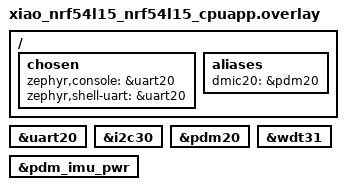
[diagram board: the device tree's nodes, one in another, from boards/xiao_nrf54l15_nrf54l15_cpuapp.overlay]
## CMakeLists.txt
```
# SPDX-License-Identifier: Apache-2.0

cmake_minimum_required(VERSION 3.20.0)

set(PM_STATIC_YML_FILE ${CMAKE_CURRENT_SOURCE_DIR}/pm_static.yml)

find_package(Zephyr REQUIRED HINTS $ENV{ZEPHYR_BASE})
project(nrf54_handy)

target_sources(app PRIVATE
    src/main.c
    src/audio_capture.c
    src/adpcm.c
)
```

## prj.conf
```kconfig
# Zephyr Kernel Configuration for XIAO nRF54L15 Sense - nrf54-handy (Handy BLE)

CONFIG_MAIN_STACK_SIZE=4096

# Heap (BLE stack + MCUmgr + audio needs memory)
CONFIG_HEAP_MEM_POOL_SIZE=65536
CONFIG_SYSTEM_WORKQUEUE_STACK_SIZE=4096

# Logging and console (UART20 on XIAO nRF54L15)
CONFIG_LOG=y
CONFIG_LOG_MODE_DEFERRED=n
CONFIG_CONSOLE=y
CONFIG_UART_CONSOLE=y
CONFIG_PRINTK=y
CONFIG_CBPRINTF_FP_SUPPORT=y

# Peripherals
CONFIG_GPIO=y
CONFIG_PINCTRL=y

# Audio (PDM microphone)
CONFIG_AUDIO=y
CONFIG_AUDIO_DMIC=y

# Bluetooth Low Energy
CONFIG_BT=y
CONFIG_BT_PERIPHERAL=y
CONFIG_BT_BROADCASTER=y
CONFIG_BT_MAX_CONN=1
CONFIG_BT_SMP=n
CONFIG_BT_GATT_DYNAMIC_DB=y
CONFIG_BT_DEVICE_NAME="XIAOVoice"
CONFIG_BT_DEVICE_NAME_DYNAMIC=y
CONFIG_BT_DEVICE_NAME_MAX=20
CONFIG_BT_GATT_CLIENT=y

# BLE MTU (OTA transfer efficiency + audio throughput)
CONFIG_BT_L2CAP_TX_MTU=244
CONFIG_BT_BUF_ACL_RX_SIZE=251
CONFIG_BT_BUF_ACL_TX_SIZE=251
CONFIG_BT_CTLR_DATA_LENGTH_MAX=251
CONFIG_BT_L2CAP_TX_BUF_COUNT=4
CONFIG_BT_ATT_TX_COUNT=4
CONFIG_BT_CONN_TX_MAX=4

# MCUmgr (SMP server for BLE OTA)
CONFIG_MCUMGR=y
CONFIG_MCUMGR_TRANSPORT_BT=y
CONFIG_MCUMGR_GRP_IMG=y
CONFIG_MCUMGR_GRP_IMG_VERBOSE_ERR=y
CONFIG_MCUBOOT_IMGTOOL_SIGN_VERSION="0.0.1+0"
CONFIG_MCUMGR_GRP_OS=y

# MCUmgr dependencies
CONFIG_IMG_MANAGER=y
CONFIG_MCUBOOT_IMG_MANAGER=y
CONFIG_FLASH=y
CONFIG_FLASH_MAP=y
CONFIG_STREAM_FLASH=y
CONFIG_NRFX_RRAMC=n
CONFIG_NRF_RRAM_READYNEXT_TIMEOUT_VALUE=0
CONFIG_NET_BUF=y
CONFIG_ZCBOR=y

# Settings persistence (image confirm state survives reboot)
CONFIG_SETTINGS=y
CONFIG_SETTINGS_FCB=y
CONFIG_FCB=y

# Watchdog timer
CONFIG_WATCHDOG=y

# Hardware info (read reset cause)
CONFIG_HWINFO=y

# I2C + IMU (LSM6DS3TR-C)
CONFIG_I2C=y
CONFIG_SENSOR=y
CONFIG_LSM6DSL=y
CONFIG_LSM6DSL_TRIGGER_GLOBAL_THREAD=y

# Regulator API (pdm_imu_pwr BLE-connected power management)
CONFIG_REGULATOR=y
```

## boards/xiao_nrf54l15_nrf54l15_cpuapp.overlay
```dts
/*
 * Device Tree Overlay for Seeed Studio XIAO nRF54L15 Sense
 * nrf54-handy: PDM microphone + IMU
 *
 * Board DTS already enables uart20, i2c30, lsm6ds3tr_c, pdm20, and imu0 alias.
 * This overlay adds the dmic20 alias used by audio_capture.c.
 */

#include <dt-bindings/gpio/gpio.h>

/ {
	chosen {
		zephyr,console = &uart20;
		zephyr,shell-uart = &uart20;
	};

	aliases {
		dmic20 = &pdm20;
	};
};

&uart20 {
	status = "okay";
};

&i2c30 {
	status = "okay";
};

&pdm20 {
	status = "okay";
};

&wdt31 {
	status = "okay";
};

/* Remove regulator-boot-on so pdm_imu_pwr starts OFF.
 * Firmware enables it explicitly on BLE connect via regulator_enable(). */
&pdm_imu_pwr {
	/delete-property/ regulator-boot-on;
};
```

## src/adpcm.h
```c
/*
 * ADPCM Codec for Voice Bridge BLE
 * IMA ADPCM 4-bit encoding/decoding
 */

#ifndef ADPCM_H
#define ADPCM_H

#include <stdint.h>
#include <stddef.h>

#ifdef __cplusplus
extern "C" {
#endif

/* ADPCM state structure */
typedef struct {
    int32_t predictor;
    int32_t step_size;
} adpcm_state_t;

/* Initialize ADPCM state */
void adpcm_init_state(adpcm_state_t *state);

/* Encode 16-bit PCM to 4-bit ADPCM */
size_t adpcm_encode(adpcm_state_t *state, const int16_t *input,
                    size_t num_samples, uint8_t *output);

/* Decode 4-bit ADPCM to 16-bit PCM */
size_t adpcm_decode(adpcm_state_t *state, const uint8_t *input,
                    size_t num_bytes, int16_t *output);

#ifdef __cplusplus
}
#endif

#endif /* ADPCM_H */
```

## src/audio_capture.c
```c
/*
 * Audio Capture for Voice Bridge BLE
 * PDM Microphone via Zephyr DMIC API on nRF54L15
 *
 * Ported from nordic-main/src/audio_capture.c:
 *   - DT alias: dmic0 → dmic20
 *   - Fallback node: pdm0 → pdm20
 *   - PDM channel: PDM_CHAN_RIGHT → PDM_CHAN_LEFT
 */

#include <zephyr/kernel.h>
#include <zephyr/device.h>
#include <zephyr/audio/dmic.h>
#include <zephyr/logging/log.h>

#include "audio_capture.h"

LOG_MODULE_REGISTER(audio_capture, LOG_LEVEL_INF);

/* ============================================================================
 * Configuration
 * ============================================================================ */

#define SAMPLE_RATE         16000
#define SAMPLE_BITS         16
#define CHANNELS            1
#define BYTES_PER_SAMPLE    sizeof(int16_t)

/* 20ms frame = 320 samples = 640 bytes */
#define FRAME_MS            20
#define FRAME_SAMPLES       (SAMPLE_RATE * FRAME_MS / 1000)
#define FRAME_BYTES         (FRAME_SAMPLES * BYTES_PER_SAMPLE * CHANNELS)

/* Memory slab for DMIC driver buffers */
#define BLOCK_COUNT         4
K_MEM_SLAB_DEFINE_STATIC(pdm_mem_slab, FRAME_BYTES, BLOCK_COUNT, 4);

/* ============================================================================
 * Global Variables
 * ============================================================================ */

static const struct device *dmic_dev;
static bool dmic_configured = false;
static bool dmic_started = false;

/* Current audio buffer from dmic_read */
static void *current_block = NULL;
static bool pdm_hw_running = false;

/* ============================================================================
 * Public API
 * ============================================================================ */

int audio_capture_init(void)
{
    if (dmic_configured) {
        return 0;
    }

#ifdef DT_N_ALIAS_dmic20
    dmic_dev = DEVICE_DT_GET(DT_ALIAS(dmic20));
#else
    dmic_dev = DEVICE_DT_GET(DT_NODELABEL(pdm20));
#endif
    if (!device_is_ready(dmic_dev)) {
        LOG_ERR("DMIC device not ready: %s", dmic_dev->name);
        printk("!!! DMIC device not ready: %s\n", dmic_dev->name);
        return -ENODEV;
    }

    struct pcm_stream_cfg stream = {
        .pcm_width = SAMPLE_BITS,
        .pcm_rate  = SAMPLE_RATE,
        .block_size = FRAME_BYTES,
        .mem_slab  = &pdm_mem_slab,
    };

    struct dmic_cfg cfg = {
        .io = {
            .min_pdm_clk_freq = 1000000,
            .max_pdm_clk_freq = 3500000,
            .min_pdm_clk_dc   = 40,
            .max_pdm_clk_dc   = 60,
        },
        .streams = &stream,
        .channel = {
            .req_num_streams = 1,
            .req_num_chan = CHANNELS,
            .req_chan_map_lo = dmic_build_channel_map(0, 0, PDM_CHAN_LEFT),
        },
    };

    int ret = dmic_configure(dmic_dev, &cfg);
    if (ret < 0) {
        LOG_ERR("DMIC configure failed: %d", ret);
        printk("!!! DMIC configure failed: %d\n", ret);
        return ret;
    }

    dmic_configured = true;

    LOG_INF("Audio capture initialized: %d Hz, %d-bit, %d ch, %d ms frames",
            SAMPLE_RATE, SAMPLE_BITS, CHANNELS, FRAME_MS);
    printk("Audio init OK: %d Hz, %d samples/frame\n", SAMPLE_RATE, FRAME_SAMPLES);
    return 0;
}

int audio_capture_start(void)
{
    if (!dmic_configured) {
        return -EIO;
    }

    if (dmic_started) {
        return 0;
    }

    int ret = dmic_trigger(dmic_dev, DMIC_TRIGGER_START);
    if (ret < 0) {
        LOG_ERR("DMIC start failed: %d", ret);
        printk("!!! DMIC start failed: %d\n", ret);
        return ret;
    }
    pdm_hw_running = true;

    /*
     * Discard frames until the PDM CIC filter's DC offset settles.
     * Fresh start produces a large negative offset (~-30000) that decays
     * ~7.5% per 20ms frame, converging to the mic's bias (~-8).
     * Discard up to 80 frames (1.6s), stopping early when |DC| < 200.
     */
    for (int i = 0; i < 80; i++) {
        void *blk = NULL;
        uint32_t sz;
        if (dmic_read(dmic_dev, 0, &blk, &sz, 100) < 0 || blk == NULL) {
            break;
        }
        int16_t *s = (int16_t *)blk;
        int32_t dc = 0;
        uint32_t n = sz / sizeof(int16_t);
        for (uint32_t j = 0; j < n; j++) {
            dc += s[j];
        }
        dc /= (int32_t)n;
        k_mem_slab_free(&pdm_mem_slab, blk);
        if (dc > -200 && dc < 200) {
            printk("PDM settled after %d frames (DC=%d)\n", i + 1, (int)dc);
            break;
        }
    }

    dmic_started = true;
    LOG_INF("Audio capture started");
    printk("Audio started\n");
    return 0;
}

int audio_capture_stop(void)
{
    if (!dmic_started) {
        return 0;
    }

    int ret = dmic_trigger(dmic_dev, DMIC_TRIGGER_STOP);
    if (ret < 0) {
        LOG_ERR("DMIC stop failed: %d", ret);
        return ret;
    }
    pdm_hw_running = false;

    if (current_block) {
        k_mem_slab_free(&pdm_mem_slab, current_block);
        current_block = NULL;
    }

    dmic_started = false;
    LOG_INF("Audio capture stopped");
    return 0;
}

int audio_capture_get_data(int16_t **buffer, size_t *size)
{
    if (!dmic_started) {
        return -EAGAIN;
    }

    if (current_block) {
        k_mem_slab_free(&pdm_mem_slab, current_block);
        current_block = NULL;
    }

    uint32_t read_size;
    int ret = dmic_read(dmic_dev, 0, &current_block, &read_size, 200);
    if (ret < 0) {
        LOG_WRN("DMIC read failed: %d", ret);
        return ret;
    }

    if (buffer) {
        *buffer = (int16_t *)current_block;
    }
    if (size) {
        *size = read_size;
    }

    return 0;
}

size_t audio_capture_get_frame_size(void)
{
    return FRAME_BYTES;
}

uint32_t audio_capture_get_sample_rate(void)
{
    return SAMPLE_RATE;
}
```

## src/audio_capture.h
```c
/*
 * Audio Capture Module for Voice Bridge BLE
 * PDM Microphone interface using Zephyr Audio Subsystem
 */

#ifndef AUDIO_CAPTURE_H
#define AUDIO_CAPTURE_H

#include <stdint.h>
#include <stddef.h>

#ifdef __cplusplus
extern "C" {
#endif

/**
 * Initialize audio capture from PDM microphone
 *
 * @return 0 on success, negative errno on failure
 */
int audio_capture_init(void);

/**
 * Start audio capture
 *
 * @return 0 on success, negative errno on failure
 */
int audio_capture_start(void);

/**
 * Stop audio capture
 *
 * @return 0 on success, negative errno on failure
 */
int audio_capture_stop(void);

/**
 * Get audio data from capture buffer
 *
 * @param buffer Pointer to receive buffer pointer
 * @param size Pointer to receive data size
 * @return 0 on success, negative errno on failure
 */
int audio_capture_get_data(int16_t **buffer, size_t *size);

/**
 * Get frame size in bytes
 *
 * @return Frame size
 */
size_t audio_capture_get_frame_size(void);

/**
 * Get sample rate
 *
 * @return Sample rate in Hz
 */
uint32_t audio_capture_get_sample_rate(void);

#ifdef __cplusplus
}
#endif

#endif /* AUDIO_CAPTURE_H */
```
